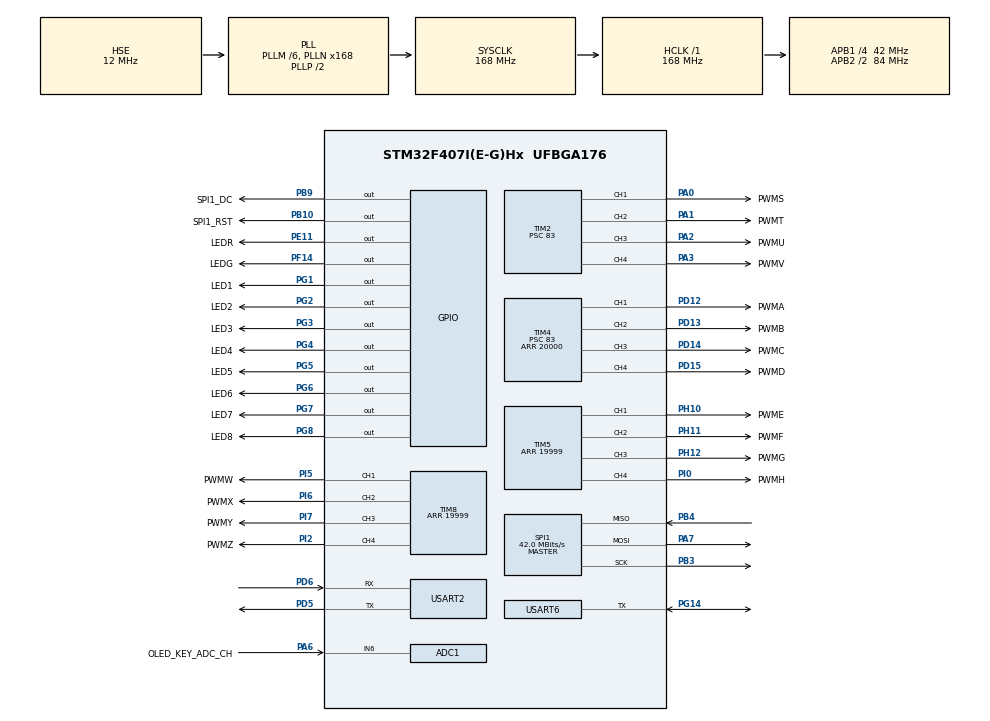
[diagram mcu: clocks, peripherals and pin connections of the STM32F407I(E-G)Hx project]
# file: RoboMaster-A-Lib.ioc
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ADC1.Channel-0\#ChannelRegularConversion=ADC_CHANNEL_6
ADC1.ContinuousConvMode=DISABLE
ADC1.ExternalTrigConv=ADC_EXTERNALTRIGCONV_T3_TRGO
ADC1.NbrOfConversion=1
ADC1.NbrOfConversionFlag=1
ADC1.Rank-0\#ChannelRegularConversion=1
ADC1.SamplingTime-0\#ChannelRegularConversion=ADC_SAMPLETIME_144CYCLES
ADC1.master=1
FREERTOS.Tasks01=defaultTask,24,128,StartDefaultTask,Default,NULL,Dynamic,NULL,NULL;appMain,8,1024,appMainFunc,Default,NULL,Static,appMainBuffer,appMainControlBlock
Mcu.Family=STM32F4
Mcu.Name=STM32F407I(E-G)Hx
Mcu.Package=UFBGA176
NVIC.ADC_IRQn=true\:5\:0\:false\:false\:true\:true\:true\:true\:true
NVIC.PriorityGroup=NVIC_PRIORITYGROUP_4
NVIC.TIM8_TRG_COM_TIM14_IRQn=true\:15\:0\:false\:false\:true\:false\:false\:true\:true
NVIC.TimeBase=TIM8_TRG_COM_TIM14_IRQn
NVIC.TimeBaseIP=TIM14
PA0-WKUP.GPIO_Label=PWMS
PA0-WKUP.Signal=S_TIM2_CH1_ETR
PA1.GPIO_Label=PWMT
PA1.Signal=S_TIM2_CH2
PA13.Mode=Serial_Wire
PA13.Signal=SYS_JTMS-SWDIO
PA14.Mode=Serial_Wire
PA14.Signal=SYS_JTCK-SWCLK
PA2.GPIO_Label=PWMU
PA2.Signal=S_TIM2_CH3
PA3.GPIO_Label=PWMV
PA3.Signal=S_TIM2_CH4
PA6.GPIO_Label=OLED_KEY_ADC_CH
PA6.Signal=ADCx_IN6
PA7.Mode=Full_Duplex_Master
PA7.Signal=SPI1_MOSI
PB10.GPIO_Label=SPI1_RST
PB10.Signal=GPIO_Output
PB3.Mode=Full_Duplex_Master
PB3.Signal=SPI1_SCK
PB4.Mode=Full_Duplex_Master
PB4.Signal=SPI1_MISO
PB9.GPIO_Label=SPI1_DC
PB9.Signal=GPIO_Output
PD12.GPIO_Label=PWMA
PD12.Signal=S_TIM4_CH1
PD13.GPIO_Label=PWMB
PD13.Signal=S_TIM4_CH2
PD14.GPIO_Label=PWMC
PD14.Signal=S_TIM4_CH3
PD15.GPIO_Label=PWMD
PD15.Signal=S_TIM4_CH4
PD5.Mode=Asynchronous
PD5.Signal=USART2_TX
PD6.Mode=Asynchronous
PD6.Signal=USART2_RX
PE11.GPIO_Label=LEDR
PE11.GPIO_ModeDefaultOutputPP=GPIO_MODE_OUTPUT_PP
PE11.GPIO_PuPd=GPIO_NOPULL
PE11.GPIO_Speed=GPIO_SPEED_FREQ_LOW
PE11.PinState=GPIO_PIN_SET
PE11.Signal=GPIO_Output
PF14.GPIO_Label=LEDG
PF14.GPIO_ModeDefaultOutputPP=GPIO_MODE_OUTPUT_PP
PF14.GPIO_PuPd=GPIO_NOPULL
PF14.GPIO_Speed=GPIO_SPEED_FREQ_LOW
PF14.PinState=GPIO_PIN_SET
PF14.Signal=GPIO_Output
PG1.GPIO_Label=LED1
PG1.GPIO_ModeDefaultOutputPP=GPIO_MODE_OUTPUT_PP
PG1.GPIO_PuPd=GPIO_NOPULL
PG1.GPIO_Speed=GPIO_SPEED_FREQ_LOW
PG1.PinState=GPIO_PIN_SET
PG1.Signal=GPIO_Output
PG14.Mode=Half_duplex(single_wire_mode)
PG14.Signal=USART6_TX
PG2.GPIO_Label=LED2
PG2.GPIO_ModeDefaultOutputPP=GPIO_MODE_OUTPUT_PP
PG2.GPIO_PuPd=GPIO_NOPULL
PG2.GPIO_Speed=GPIO_SPEED_FREQ_LOW
PG2.PinState=GPIO_PIN_SET
PG2.Signal=GPIO_Output
PG3.GPIO_Label=LED3
PG3.GPIO_ModeDefaultOutputPP=GPIO_MODE_OUTPUT_PP
PG3.GPIO_PuPd=GPIO_NOPULL
PG3.GPIO_Speed=GPIO_SPEED_FREQ_LOW
PG3.PinState=GPIO_PIN_SET
PG3.Signal=GPIO_Output
PG4.GPIO_Label=LED4
PG4.GPIO_ModeDefaultOutputPP=GPIO_MODE_OUTPUT_PP
PG4.GPIO_PuPd=GPIO_NOPULL
PG4.GPIO_Speed=GPIO_SPEED_FREQ_LOW
PG4.PinState=GPIO_PIN_SET
PG4.Signal=GPIO_Output
PG5.GPIO_Label=LED5
PG5.GPIO_ModeDefaultOutputPP=GPIO_MODE_OUTPUT_PP
PG5.GPIO_PuPd=GPIO_NOPULL
PG5.GPIO_Speed=GPIO_SPEED_FREQ_LOW
PG5.PinState=GPIO_PIN_SET
PG5.Signal=GPIO_Output
PG6.GPIO_Label=LED6
PG6.GPIO_ModeDefaultOutputPP=GPIO_MODE_OUTPUT_PP
PG6.GPIO_PuPd=GPIO_NOPULL
PG6.GPIO_Speed=GPIO_SPEED_FREQ_LOW
PG6.PinState=GPIO_PIN_SET
PG6.Signal=GPIO_Output
PG7.GPIO_Label=LED7
PG7.GPIO_ModeDefaultOutputPP=GPIO_MODE_OUTPUT_PP
PG7.GPIO_PuPd=GPIO_NOPULL
PG7.GPIO_Speed=GPIO_SPEED_FREQ_LOW
PG7.PinState=GPIO_PIN_SET
PG7.Signal=GPIO_Output
PG8.GPIO_Label=LED8
PG8.GPIO_ModeDefaultOutputPP=GPIO_MODE_OUTPUT_PP
PG8.GPIO_PuPd=GPIO_NOPULL
PG8.GPIO_Speed=GPIO_SPEED_FREQ_LOW
PG8.PinState=GPIO_PIN_SET
PG8.Signal=GPIO_Output
PH0-OSC_IN.Mode=HSE-External-Oscillator
PH0-OSC_IN.Signal=RCC_OSC_IN
PH1-OSC_OUT.Mode=HSE-External-Oscillator
PH1-OSC_OUT.Signal=RCC_OSC_OUT
PH10.GPIO_Label=PWME
PH10.Signal=S_TIM5_CH1
PH11.GPIO_Label=PWMF
PH11.Signal=S_TIM5_CH2
PH12.GPIO_Label=PWMG
PH12.Signal=S_TIM5_CH3
PI0.GPIO_Label=PWMH
PI0.Signal=S_TIM5_CH4
PI2.GPIO_Label=PWMZ
PI2.Signal=S_TIM8_CH4
PI5.GPIO_Label=PWMW
PI5.Signal=S_TIM8_CH1
PI6.GPIO_Label=PWMX
PI6.Signal=S_TIM8_CH2
PI7.GPIO_Label=PWMY
PI7.Signal=S_TIM8_CH3
ProjectManager.HeapSize=0x1000
ProjectManager.StackSize=0x2000
ProjectManager.TargetToolchain=CMake
RCC.48MHZClocksFreq_Value=84000000
RCC.AHBFreq_Value=168000000
RCC.APB1CLKDivider=RCC_HCLK_DIV4
RCC.APB1Freq_Value=42000000
RCC.APB1TimFreq_Value=84000000
RCC.APB2CLKDivider=RCC_HCLK_DIV2
RCC.APB2Freq_Value=84000000
RCC.APB2TimFreq_Value=168000000
RCC.CortexFreq_Value=168000000
RCC.HCLKFreq_Value=168000000
RCC.HSE_VALUE=12000000
RCC.HSI_VALUE=16000000
RCC.LSE_VALUE=32768
RCC.PLLM=6
RCC.PLLN=168
RCC.PLLSourceVirtual=RCC_PLLSOURCE_HSE
RCC.SYSCLKFreq_VALUE=168000000
RCC.SYSCLKSource=RCC_SYSCLKSOURCE_PLLCLK
RCC.VCOOutputFreq_Value=336000000
SH.ADCx_IN6.0=ADC1_IN6,IN6
SH.S_TIM2_CH1_ETR.0=TIM2_CH1,PWM Generation1 CH1
SH.S_TIM2_CH2.0=TIM2_CH2,PWM Generation2 CH2
SH.S_TIM2_CH3.0=TIM2_CH3,PWM Generation3 CH3
SH.S_TIM2_CH4.0=TIM2_CH4,PWM Generation4 CH4
SH.S_TIM4_CH1.0=TIM4_CH1,PWM Generation1 CH1
SH.S_TIM4_CH2.0=TIM4_CH2,PWM Generation2 CH2
SH.S_TIM4_CH3.0=TIM4_CH3,PWM Generation3 CH3
SH.S_TIM4_CH4.0=TIM4_CH4,PWM Generation4 CH4
SH.S_TIM5_CH1.0=TIM5_CH1,PWM Generation1 CH1
SH.S_TIM5_CH2.0=TIM5_CH2,PWM Generation2 CH2
SH.S_TIM5_CH3.0=TIM5_CH3,PWM Generation3 CH3
SH.S_TIM5_CH4.0=TIM5_CH4,PWM Generation4 CH4
SH.S_TIM8_CH1.0=TIM8_CH1,PWM Generation1 CH1
SH.S_TIM8_CH2.0=TIM8_CH2,PWM Generation2 CH2
SH.S_TIM8_CH3.0=TIM8_CH3,PWM Generation3 CH3
SH.S_TIM8_CH4.0=TIM8_CH4,PWM Generation4 CH4
SPI1.BaudRatePrescaler=SPI_BAUDRATEPRESCALER_2
SPI1.CalculateBaudRate=42.0 MBits/s
SPI1.Direction=SPI_DIRECTION_2LINES
SPI1.Mode=SPI_MODE_MASTER
SPI1.VirtualType=VM_MASTER
TIM2.Channel-PWM\ Generation1\ CH1=TIM_CHANNEL_1
TIM2.Channel-PWM\ Generation2\ CH2=TIM_CHANNEL_2
TIM2.Channel-PWM\ Generation3\ CH3=TIM_CHANNEL_3
TIM2.Channel-PWM\ Generation4\ CH4=TIM_CHANNEL_4
TIM2.Prescaler=83
TIM3.Period=1000-1
TIM3.Prescaler=8400-1
TIM3.TIM_MasterOutputTrigger=TIM_TRGO_UPDATE
TIM3.TIM_MasterSlaveMode=TIM_MASTERSLAVEMODE_DISABLE
TIM4.Channel-PWM\ Generation1\ CH1=TIM_CHANNEL_1
TIM4.Channel-PWM\ Generation2\ CH2=TIM_CHANNEL_2
TIM4.Channel-PWM\ Generation3\ CH3=TIM_CHANNEL_3
TIM4.Channel-PWM\ Generation4\ CH4=TIM_CHANNEL_4
TIM4.Period=20000
TIM4.Prescaler=83
TIM5.Channel-PWM\ Generation1\ CH1=TIM_CHANNEL_1
TIM5.Channel-PWM\ Generation2\ CH2=TIM_CHANNEL_2
TIM5.Channel-PWM\ Generation3\ CH3=TIM_CHANNEL_3
TIM5.Channel-PWM\ Generation4\ CH4=TIM_CHANNEL_4
TIM5.Period=19999
TIM8.Channel-PWM\ Generation1\ CH1=TIM_CHANNEL_1
TIM8.Channel-PWM\ Generation2\ CH2=TIM_CHANNEL_2
TIM8.Channel-PWM\ Generation3\ CH3=TIM_CHANNEL_3
TIM8.Channel-PWM\ Generation4\ CH4=TIM_CHANNEL_4
TIM8.Period=19999
USART2.VirtualMode=VM_ASYNC
USART6.BaudRate=500000
USART6.VirtualMode=VM_ASYNC
VP_FREERTOS_VS_CMSIS_V2.Mode=CMSIS_V2
VP_SYS_VS_tim14.Mode=TIM14
VP_TIM2_VS_ClockSourceINT.Mode=Internal
VP_TIM3_VS_ClockSourceINT.Mode=Internal
VP_TIM4_VS_ClockSourceINT.Mode=Internal
VP_TIM5_VS_ClockSourceINT.Mode=Internal
VP_TIM8_VS_ClockSourceINT.Mode=Internal
board=custom

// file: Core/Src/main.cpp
/* USER CODE BEGIN Header */
/**
  ******************************************************************************
  * @file           : main.c
  * @brief          : Main program body
  ******************************************************************************
  * @attention
  *
  * Copyright (c) 2025 STMicroelectronics.
  * All rights reserved.
  *
  * This software is licensed under terms that can be found in the LICENSE file
  * in the root directory of this software component.
  * If no LICENSE file comes with this software, it is provided AS-IS.
  *
  ******************************************************************************
  */
/* USER CODE END Header */
#include "main.h"
#include "cmsis_os.h"
#include "adc.h"
#include "spi.h"
#include "tim.h"
#include "usart.h"
#include "gpio.h"

void SystemClock_Config(void);
void MX_FREERTOS_Init(void);

int main(void)
{

  /* MCU Configuration--------------------------------------------------------*/

  /* Reset of all peripherals, Initializes the Flash interface and the Systick. */
  HAL_Init();

  /* Configure the system clock */
  SystemClock_Config();

  /* Initialize all configured peripherals */
  MX_GPIO_Init();
  MX_TIM5_Init();
  MX_TIM2_Init();
  MX_TIM4_Init();
  MX_TIM8_Init();
  MX_USART2_UART_Init();
  MX_SPI1_Init();
  MX_ADC1_Init();
  MX_TIM3_Init();
  MX_USART6_UART_Init();

  /* Init scheduler */
  osKernelInitialize();

  /* Call init function for freertos objects (in cmsis_os2.c) */
  MX_FREERTOS_Init();

  /* Start scheduler */
  osKernelStart();

  /* We should never get here as control is now taken by the scheduler */

  /* Infinite loop */
  while (1)
  {

  }
}

void SystemClock_Config(void)
{
  RCC_OscInitTypeDef RCC_OscInitStruct = {0};
  RCC_ClkInitTypeDef RCC_ClkInitStruct = {0};

  /** Configure the main internal regulator output voltage
  */
  __HAL_RCC_PWR_CLK_ENABLE();
  __HAL_PWR_VOLTAGESCALING_CONFIG(PWR_REGULATOR_VOLTAGE_SCALE1);

  /** Initializes the RCC Oscillators according to the specified parameters
  * in the RCC_OscInitTypeDef structure.
  */
  RCC_OscInitStruct.OscillatorType = RCC_OSCILLATORTYPE_HSE;
  RCC_OscInitStruct.HSEState = RCC_HSE_ON;
  RCC_OscInitStruct.PLL.PLLState = RCC_PLL_ON;
  RCC_OscInitStruct.PLL.PLLSource = RCC_PLLSOURCE_HSE;
  RCC_OscInitStruct.PLL.PLLM = 6;
  RCC_OscInitStruct.PLL.PLLN = 168;
  RCC_OscInitStruct.PLL.PLLP = RCC_PLLP_DIV2;
  RCC_OscInitStruct.PLL.PLLQ = 4;
  if (HAL_RCC_OscConfig(&RCC_OscInitStruct) != HAL_OK)
  {
    Error_Handler();
  }

  /** Initializes the CPU, AHB and APB buses clocks
  */
  RCC_ClkInitStruct.ClockType = RCC_CLOCKTYPE_HCLK|RCC_CLOCKTYPE_SYSCLK
                              |RCC_CLOCKTYPE_PCLK1|RCC_CLOCKTYPE_PCLK2;
  RCC_ClkInitStruct.SYSCLKSource = RCC_SYSCLKSOURCE_PLLCLK;
  RCC_ClkInitStruct.AHBCLKDivider = RCC_SYSCLK_DIV1;
  RCC_ClkInitStruct.APB1CLKDivider = RCC_HCLK_DIV4;
  RCC_ClkInitStruct.APB2CLKDivider = RCC_HCLK_DIV2;

  if (HAL_RCC_ClockConfig(&RCC_ClkInitStruct, FLASH_LATENCY_5) != HAL_OK)
  {
    Error_Handler();
  }
}

void HAL_TIM_PeriodElapsedCallback(TIM_HandleTypeDef *htim)
{
  if (htim->Instance == TIM14)
  {
    HAL_IncTick();
  }
}

void Error_Handler(void)
{
  __disable_irq();
  while (1)
  {
  }
}

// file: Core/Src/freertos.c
/* USER CODE BEGIN Header */
/**
  ******************************************************************************
  * File Name          : freertos.c
  * Description        : Code for freertos applications
  ******************************************************************************
  * @attention
  *
  * Copyright (c) 2025 STMicroelectronics.
  * All rights reserved.
  *
  * This software is licensed under terms that can be found in the LICENSE file
  * in the root directory of this software component.
  * If no LICENSE file comes with this software, it is provided AS-IS.
  *
  ******************************************************************************
  */
/* USER CODE END Header */

#include "FreeRTOS.h"
#include "task.h"
#include "main.h"
#include "cmsis_os.h"

typedef StaticTask_t osStaticThreadDef_t;

/* Definitions for defaultTask */
osThreadId_t defaultTaskHandle;
const osThreadAttr_t defaultTask_attributes = {
  .name = "defaultTask",
  .stack_size = 128 * 4,
  .priority = (osPriority_t) osPriorityNormal,
};
/* Definitions for appMain */
osThreadId_t appMainHandle;
uint32_t appMainBuffer[ 1024 ];
osStaticThreadDef_t appMainControlBlock;
const osThreadAttr_t appMain_attributes = {
  .name = "appMain",
  .cb_mem = &appMainControlBlock,
  .cb_size = sizeof(appMainControlBlock),
  .stack_mem = &appMainBuffer[0],
  .stack_size = sizeof(appMainBuffer),
  .priority = (osPriority_t) osPriorityLow,
};

/* USER CODE BEGIN FunctionPrototypes */

#include "stdio.h"

/* USER CODE END FunctionPrototypes */

void StartDefaultTask(void *argument);
void appMainFunc(void *argument);

void MX_FREERTOS_Init(void); /* (MISRA C 2004 rule 8.1) */

void MX_FREERTOS_Init(void) {

  /* Create the thread(s) */
  /* creation of defaultTask */
  defaultTaskHandle = osThreadNew(StartDefaultTask, NULL, &defaultTask_attributes);

  /* creation of appMain */
  appMainHandle = osThreadNew(appMainFunc, NULL, &appMain_attributes);

  HAL_OK

}

void StartDefaultTask(void *argument)
{
  for(;;)
  {
    osDelay(1);
  }
}

void appMainFunc(void *argument)
{
  for(;;)
  {
    osDelay(1);
  }
}
